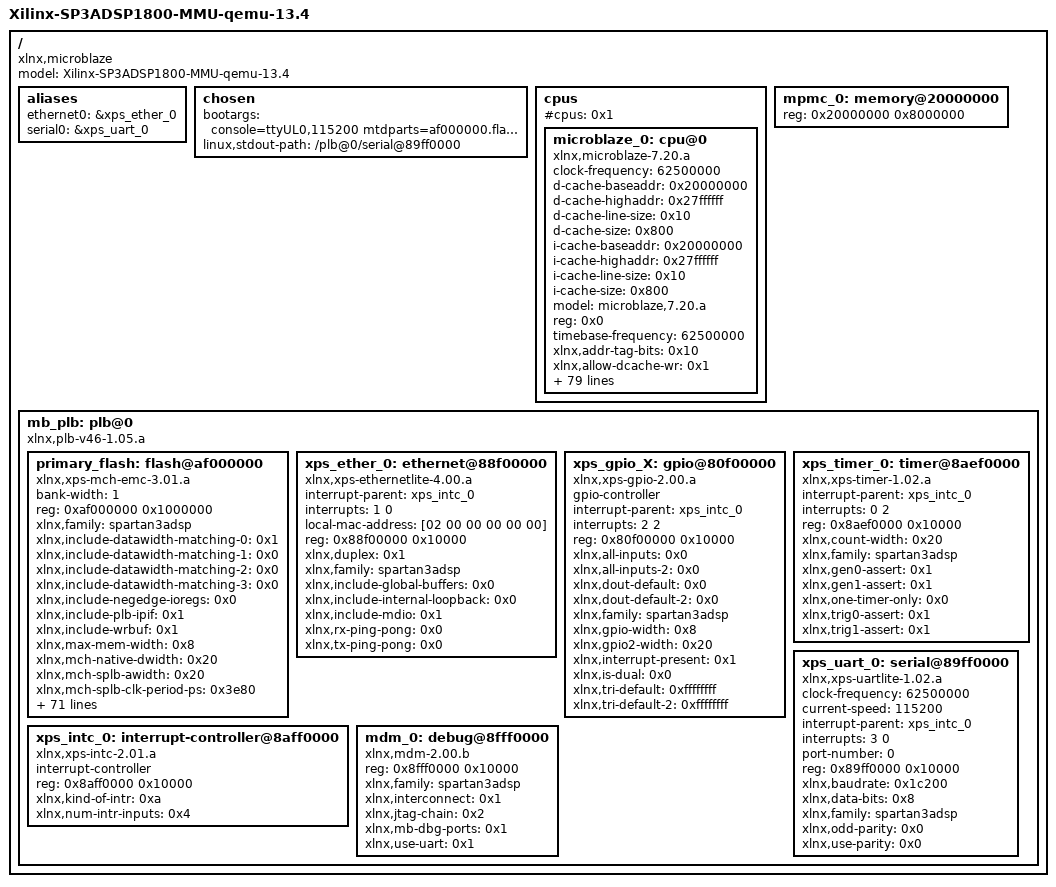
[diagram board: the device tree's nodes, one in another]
/*
 * Device Tree Generator version: none
 *
 * This file was manually converted from QEMU's petalogix-s3adsp1800.dtb
 * and manually changed on some places:
 *  - dtc -I dtb -O dts -o petalogix-s3adsp1800.dts petalogix-s3adsp1800.dtb
 *  - frequency values from hex to dec: 0x3b9aca0 --> 62500000
 *  - speed values from hex to dec: 0x1c200 --> 115200
 *  - modell from "testing" to "Xilinx-SP3ADSP1800-MMU-qemu-13.4"
 *  - add names of instances: microblaze_0, mpmc_0, mb_plb, mdm_0,
 *    xps_intc_0, xps_timer_0, primary_flash, xps_ether_0, xps_gpio_X,
 *    xps_uart_0
 *  - bootargs: add option debug
 *
 * (C) Copyright 2012 Li-Pro.Net
 * Stephan Linz <linz@li-pro.net>
 *
 * This program is free software; you can redistribute it and/or
 * modify it under the terms of the GNU General Public License as
 * published by the Free Software Foundation; either version 2 of
 * the License, or (at your option) any later version.
 *
 * This program is distributed in the hope that it will be useful,
 * but WITHOUT ANY WARRANTY; without even the implied warranty of
 * MERCHANTABILITY or FITNESS FOR A PARTICULAR PURPOSE. See the
 * GNU General Public License for more details.
 *
 * You should have received a copy of the GNU General Public License
 * along with this program; if not, write to the Free Software
 * Foundation, Inc., 59 Temple Place, Suite 330, Boston,
 * MA 02111-1307 USA
 *
 * Version:  Xilinx EDK 13.4 ... (details unknown)
 * Today is: Wednesday, the 19 of Dezember, 2012; 16:13:37
 */

/dts-v1/;

/ {
	#address-cells = <0x1>;
	#size-cells = <0x1>;
	compatible = "xlnx,microblaze";
	model = "Xilinx-SP3ADSP1800-MMU-qemu-13.4";

	aliases {
		ethernet0 = &xps_ether_0;
		serial0 = &xps_uart_0;
	};

	chosen {
		bootargs = "console=ttyUL0,115200 mtdparts=af000000.flash:16384k(all)ro debug";
		linux,stdout-path = "/plb@0/serial@89ff0000";
	};

	cpus {
		#address-cells = <0x1>;
		#cpus = <0x1>;
		#size-cells = <0x0>;

		microblaze_0: cpu@0 {
			clock-frequency = <62500000>;
			compatible = "xlnx,microblaze-7.20.a";
			d-cache-baseaddr = <0x20000000>;
			d-cache-highaddr = <0x27ffffff>;
			d-cache-line-size = <0x10>;
			d-cache-size = <0x800>;
			device_type = "cpu";
			i-cache-baseaddr = <0x20000000>;
			i-cache-highaddr = <0x27ffffff>;
			i-cache-line-size = <0x10>;
			i-cache-size = <0x800>;
			model = "microblaze,7.20.a";
			reg = <0x0>;
			timebase-frequency = <62500000>;
			xlnx,addr-tag-bits = <0x10>;
			xlnx,allow-dcache-wr = <0x1>;
			xlnx,allow-icache-wr = <0x1>;
			xlnx,area-optimized = <0x0>;
			xlnx,avoid-primitives = <0x0>;
			xlnx,branch-target-cache-size = <0x0>;
			xlnx,cache-byte-size = <0x800>;
			xlnx,d-axi = <0x0>;
			xlnx,d-lmb = <0x1>;
			xlnx,d-plb = <0x1>;
			xlnx,data-size = <0x20>;
			xlnx,dcache-addr-tag = <0x10>;
			xlnx,dcache-always-used = <0x0>;
			xlnx,dcache-byte-size = <0x800>;
			xlnx,dcache-data-width = <0x0>;
			xlnx,dcache-force-tag-lutram = <0x0>;
			xlnx,dcache-interface = <0x0>;
			xlnx,dcache-line-len = <0x4>;
			xlnx,dcache-use-fsl = <0x1>;
			xlnx,dcache-use-writeback = <0x0>;
			xlnx,dcache-victims = <0x0>;
			xlnx,debug-enabled = <0x1>;
			xlnx,div-zero-exception = <0x0>;
			xlnx,dynamic-bus-sizing = <0x1>;
			xlnx,ecc-use-ce-exception = <0x0>;
			xlnx,edge-is-positive = <0x1>;
			xlnx,family = "spartan3adsp";
			xlnx,fault-tolerant = <0x0>;
			xlnx,fpu-exception = <0x0>;
			xlnx,freq = <0x3b9aca0>;
			xlnx,fsl-data-size = <0x20>;
			xlnx,fsl-exception = <0x0>;
			xlnx,fsl-links = <0x0>;
			xlnx,i-axi = <0x0>;
			xlnx,i-lmb = <0x1>;
			xlnx,i-plb = <0x1>;
			xlnx,icache-always-used = <0x0>;
			xlnx,icache-data-width = <0x0>;
			xlnx,icache-force-tag-lutram = <0x0>;
			xlnx,icache-interface = <0x0>;
			xlnx,icache-line-len = <0x4>;
			xlnx,icache-streams = <0x0>;
			xlnx,icache-use-fsl = <0x1>;
			xlnx,icache-victims = <0x0>;
			xlnx,ill-opcode-exception = <0x0>;
			xlnx,instance = "microblaze_0";
			xlnx,interconnect = <0x1>;
			xlnx,interrupt-is-edge = <0x0>;
			xlnx,lockstep-slave = <0x0>;
			xlnx,mmu-dtlb-size = <0x4>;
			xlnx,mmu-itlb-size = <0x2>;
			xlnx,mmu-privileged-instr = <0x0>;
			xlnx,mmu-tlb-access = <0x3>;
			xlnx,mmu-zones = <0x10>;
			xlnx,number-of-pc-brk = <0x3>;
			xlnx,number-of-rd-addr-brk = <0x2>;
			xlnx,number-of-wr-addr-brk = <0x2>;
			xlnx,opcode-0x0-illegal = <0x0>;
			xlnx,optimization = <0x0>;
			xlnx,pvr = <0x1>;
			xlnx,pvr-user1 = <0x0>;
			xlnx,pvr-user2 = <0x0>;
			xlnx,reset-msr = <0x0>;
			xlnx,sco = <0x0>;
			xlnx,stream-interconnect = <0x0>;
			xlnx,unaligned-exceptions = <0x1>;
			xlnx,use-barrel = <0x1>;
			xlnx,use-branch-target-cache = <0x0>;
			xlnx,use-dcache = <0x1>;
			xlnx,use-div = <0x0>;
			xlnx,use-ext-brk = <0x1>;
			xlnx,use-ext-nm-brk = <0x1>;
			xlnx,use-extended-fsl-instr = <0x0>;
			xlnx,use-fpu = <0x0>;
			xlnx,use-hw-mul = <0x1>;
			xlnx,use-icache = <0x1>;
			xlnx,use-interrupt = <0x1>;
			xlnx,use-mmu = <0x3>;
			xlnx,use-msr-instr = <0x1>;
			xlnx,use-pcmp-instr = <0x1>;
			xlnx,use-stack-protection = <0x0>;
		};
	};

	mpmc_0: memory@20000000 {
		device_type = "memory";
		reg = <0x20000000 0x8000000>;
	};

	mb_plb: plb@0 {
		#address-cells = <0x1>;
		#size-cells = <0x1>;
		compatible = "xlnx,plb-v46-1.05.a", "xlnx,plb-v46-1.00.a", "simple-bus";
		ranges;

		primary_flash: flash@af000000 {
			bank-width = <1>;
			compatible = "xlnx,xps-mch-emc-3.01.a", "cfi-flash";
			reg = <0xaf000000 0x1000000>;
			xlnx,family = "spartan3adsp";
			xlnx,include-datawidth-matching-0 = <0x1>;
			xlnx,include-datawidth-matching-1 = <0x0>;
			xlnx,include-datawidth-matching-2 = <0x0>;
			xlnx,include-datawidth-matching-3 = <0x0>;
			xlnx,include-negedge-ioregs = <0x0>;
			xlnx,include-plb-ipif = <0x1>;
			xlnx,include-wrbuf = <0x1>;
			xlnx,max-mem-width = <0x8>;
			xlnx,mch-native-dwidth = <0x20>;
			xlnx,mch-splb-awidth = <0x20>;
			xlnx,mch-splb-clk-period-ps = <0x3e80>;
			xlnx,mch0-accessbuf-depth = <0x10>;
			xlnx,mch0-protocol = <0x0>;
			xlnx,mch0-rddatabuf-depth = <0x10>;
			xlnx,mch1-accessbuf-depth = <0x10>;
			xlnx,mch1-protocol = <0x0>;
			xlnx,mch1-rddatabuf-depth = <0x10>;
			xlnx,mch2-accessbuf-depth = <0x10>;
			xlnx,mch2-protocol = <0x0>;
			xlnx,mch2-rddatabuf-depth = <0x10>;
			xlnx,mch3-accessbuf-depth = <0x10>;
			xlnx,mch3-protocol = <0x0>;
			xlnx,mch3-rddatabuf-depth = <0x10>;
			xlnx,mem0-width = <0x8>;
			xlnx,mem1-width = <0x20>;
			xlnx,mem2-width = <0x20>;
			xlnx,mem3-width = <0x20>;
			xlnx,num-banks-mem = <0x1>;
			xlnx,num-channels = <0x0>;
			xlnx,pagemode-flash-0 = <0x0>;
			xlnx,pagemode-flash-1 = <0x0>;
			xlnx,pagemode-flash-2 = <0x0>;
			xlnx,pagemode-flash-3 = <0x0>;
			xlnx,priority-mode = <0x0>;
			xlnx,synch-mem-0 = <0x0>;
			xlnx,synch-mem-1 = <0x0>;
			xlnx,synch-mem-2 = <0x0>;
			xlnx,synch-mem-3 = <0x0>;
			xlnx,synch-pipedelay-0 = <0x2>;
			xlnx,synch-pipedelay-1 = <0x2>;
			xlnx,synch-pipedelay-2 = <0x2>;
			xlnx,synch-pipedelay-3 = <0x2>;
			xlnx,tavdv-ps-mem-0 = <0x11170>;
			xlnx,tavdv-ps-mem-1 = <0x3a98>;
			xlnx,tavdv-ps-mem-2 = <0x3a98>;
			xlnx,tavdv-ps-mem-3 = <0x3a98>;
			xlnx,tcedv-ps-mem-0 = <0x11170>;
			xlnx,tcedv-ps-mem-1 = <0x3a98>;
			xlnx,tcedv-ps-mem-2 = <0x3a98>;
			xlnx,tcedv-ps-mem-3 = <0x3a98>;
			xlnx,thzce-ps-mem-0 = <0x61a8>;
			xlnx,thzce-ps-mem-1 = <0x1b58>;
			xlnx,thzce-ps-mem-2 = <0x1b58>;
			xlnx,thzce-ps-mem-3 = <0x1b58>;
			xlnx,thzoe-ps-mem-0 = <0x61a8>;
			xlnx,thzoe-ps-mem-1 = <0x1b58>;
			xlnx,thzoe-ps-mem-2 = <0x1b58>;
			xlnx,thzoe-ps-mem-3 = <0x1b58>;
			xlnx,tlzwe-ps-mem-0 = <0x1388>;
			xlnx,tlzwe-ps-mem-1 = <0x0>;
			xlnx,tlzwe-ps-mem-2 = <0x0>;
			xlnx,tlzwe-ps-mem-3 = <0x0>;
			xlnx,tpacc-ps-flash-0 = <0x61a8>;
			xlnx,tpacc-ps-flash-1 = <0x61a8>;
			xlnx,tpacc-ps-flash-2 = <0x61a8>;
			xlnx,tpacc-ps-flash-3 = <0x61a8>;
			xlnx,twc-ps-mem-0 = <0x11170>;
			xlnx,twc-ps-mem-1 = <0x3a98>;
			xlnx,twc-ps-mem-2 = <0x3a98>;
			xlnx,twc-ps-mem-3 = <0x3a98>;
			xlnx,twp-ps-mem-0 = <0xafc8>;
			xlnx,twp-ps-mem-1 = <0x2ee0>;
			xlnx,twp-ps-mem-2 = <0x2ee0>;
			xlnx,twp-ps-mem-3 = <0x2ee0>;
			xlnx,xcl0-linesize = <0x4>;
			xlnx,xcl0-writexfer = <0x1>;
			xlnx,xcl1-linesize = <0x4>;
			xlnx,xcl1-writexfer = <0x1>;
			xlnx,xcl2-linesize = <0x4>;
			xlnx,xcl2-writexfer = <0x1>;
			xlnx,xcl3-linesize = <0x4>;
			xlnx,xcl3-writexfer = <0x1>;
		};

		xps_ether_0: ethernet@88f00000 {
			compatible = "xlnx,xps-ethernetlite-4.00.a", "xlnx,xps-ethernetlite-1.00.a";
			device_type = "network";
			interrupt-parent = <&xps_intc_0>;
			interrupts = <1 0>;
			local-mac-address = [02 00 00 00 00 00];
			reg = <0x88f00000 0x10000>;
			xlnx,duplex = <0x1>;
			xlnx,family = "spartan3adsp";
			xlnx,include-global-buffers = <0x0>;
			xlnx,include-internal-loopback = <0x0>;
			xlnx,include-mdio = <0x1>;
			xlnx,rx-ping-pong = <0x0>;
			xlnx,tx-ping-pong = <0x0>;
			/* we do not define a specific PHY, because Qemu does not know it */
		};

		xps_gpio_X: gpio@80f00000 {
			#gpio-cells = <2>;
			compatible = "xlnx,xps-gpio-2.00.a", "xlnx,xps-gpio-1.00.a";
			gpio-controller ;
			interrupt-parent = <&xps_intc_0>;
			interrupts = <2 2>;
			reg = <0x80f00000 0x10000>;
			xlnx,all-inputs = <0x0>;
			xlnx,all-inputs-2 = <0x0>;
			xlnx,dout-default = <0x0>;
			xlnx,dout-default-2 = <0x0>;
			xlnx,family = "spartan3adsp";
			xlnx,gpio-width = <0x8>;
			xlnx,gpio2-width = <0x20>;
			xlnx,interrupt-present = <0x1>;
			xlnx,is-dual = <0x0>;
			xlnx,tri-default = <0xffffffff>;
			xlnx,tri-default-2 = <0xffffffff>;
		};

		xps_intc_0: interrupt-controller@8aff0000 {
			#interrupt-cells = <0x2>;
			compatible = "xlnx,xps-intc-2.01.a", "xlnx,xps-intc-1.00.a";
			interrupt-controller;
			reg = <0x8aff0000 0x10000>;
			xlnx,kind-of-intr = <0xa>;
			xlnx,num-intr-inputs = <0x4>;
			linux,phandle = <0x1>;
		};

		xps_timer_0: timer@8aef0000 {
			compatible = "xlnx,xps-timer-1.02.a", "xlnx,xps-timer-1.00.a";
			interrupt-parent = <&xps_intc_0>;
			interrupts = <0 2>;
			reg = <0x8aef0000 0x10000>;
			xlnx,count-width = <0x20>;
			xlnx,family = "spartan3adsp";
			xlnx,gen0-assert = <0x1>;
			xlnx,gen1-assert = <0x1>;
			xlnx,one-timer-only = <0x0>;
			xlnx,trig0-assert = <0x1>;
			xlnx,trig1-assert = <0x1>;
		};

		/* leave the uartlite before mdm, because of parsing problems in Qemu */
		xps_uart_0: serial@89ff0000 {
			clock-frequency = <62500000>;
			compatible = "xlnx,xps-uartlite-1.02.a", "xlnx,xps-uartlite-1.00.a";
			current-speed = <115200>;
			device_type = "serial";
			interrupt-parent = <&xps_intc_0>;
			interrupts = <3 0>;
			port-number = <0>;
			reg = <0x89ff0000 0x10000>;
			xlnx,baudrate = <0x1c200>;
			xlnx,data-bits = <0x8>;
			xlnx,family = "spartan3adsp";
			xlnx,odd-parity = <0x0>;
			xlnx,use-parity = <0x0>;
		};

		/* leave the mdm behind uartlite, because of parsing problems in Qemu */
		mdm_0: debug@8fff0000 {
			compatible = "xlnx,mdm-2.00.b", "xlnx,xps-uartlite-1.00.a";
			reg = <0x8fff0000 0x10000>;
			xlnx,family = "spartan3adsp";
			xlnx,interconnect = <0x1>;
			xlnx,jtag-chain = <0x2>;
			xlnx,mb-dbg-ports = <0x1>;
			xlnx,use-uart = <0x1>;
		};
	};
};
